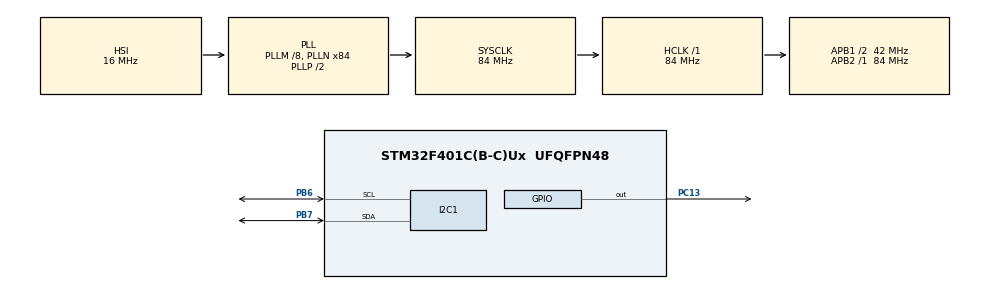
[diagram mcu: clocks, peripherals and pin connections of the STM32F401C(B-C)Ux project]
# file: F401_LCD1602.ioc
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Mcu.Family=STM32F4
Mcu.Name=STM32F401C(B-C)Ux
Mcu.Package=UFQFPN48
NVIC.PriorityGroup=NVIC_PRIORITYGROUP_4
PB6.Mode=I2C
PB6.Signal=I2C1_SCL
PB7.Mode=I2C
PB7.Signal=I2C1_SDA
PC13-ANTI_TAMP.Signal=GPIO_Output
PH0\ -\ OSC_IN.Mode=HSE-External-Oscillator
PH0\ -\ OSC_IN.Signal=RCC_OSC_IN
PH1\ -\ OSC_OUT.Mode=HSE-External-Oscillator
PH1\ -\ OSC_OUT.Signal=RCC_OSC_OUT
ProjectManager.HeapSize=0x200
ProjectManager.StackSize=0x400
ProjectManager.TargetToolchain=STM32CubeIDE
RCC.48MHZClocksFreq_Value=42000000
RCC.AHBFreq_Value=84000000
RCC.APB1CLKDivider=RCC_HCLK_DIV2
RCC.APB1Freq_Value=42000000
RCC.APB1TimFreq_Value=84000000
RCC.APB2Freq_Value=84000000
RCC.APB2TimFreq_Value=84000000
RCC.CortexFreq_Value=84000000
RCC.HCLKFreq_Value=84000000
RCC.HSE_VALUE=25000000
RCC.HSI_VALUE=16000000
RCC.LSE_VALUE=32768
RCC.PLLM=8
RCC.PLLN=84
RCC.SYSCLKFreq_VALUE=84000000
RCC.SYSCLKSource=RCC_SYSCLKSOURCE_PLLCLK
RCC.VCOOutputFreq_Value=168000000
board=custom

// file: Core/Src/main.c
/* USER CODE BEGIN Header */
/**
  ******************************************************************************
  * @file           : main.c
  * @brief          : Main program body
  ******************************************************************************
  * @attention
  *
  * <h2><center>&copy; Copyright (c) 2023 STMicroelectronics.
  * All rights reserved.</center></h2>
  *
  * This software component is licensed by ST under BSD 3-Clause license,
  * the "License"; You may not use this file except in compliance with the
  * License. You may obtain a copy of the License at:
  *                        opensource.org/licenses/BSD-3-Clause
  *
  ******************************************************************************
  */
/* USER CODE END Header */
#include "main.h"
#include "i2c.h"
#include "gpio.h"

/* USER CODE BEGIN Includes */
#include "LCD1602.h"
/* USER CODE END Includes */

/* USER CODE BEGIN PTD */
#define LCD_GREEN_ADDRESS (0x27 << 1)
#define LCD_BLUE_ADDRESS (0x26 << 1)
/* USER CODE END PTD */

void SystemClock_Config(void);

int main(void)
{

  /* MCU Configuration--------------------------------------------------------*/

  /* Reset of all peripherals, Initializes the Flash interface and the Systick. */
  HAL_Init();

  /* Configure the system clock */
  SystemClock_Config();

  /* Initialize all configured peripherals */
  MX_GPIO_Init();
  MX_I2C1_Init();
  /* USER CODE BEGIN 2 */
  LCD_Init(&hi2c1, LCD_GREEN_ADDRESS);
  LCD_Init(&hi2c1, LCD_BLUE_ADDRESS);
  HAL_Delay(1000);
  /* USER CODE END 2 */

  /* Infinite loop */
  while (1)
  {

    /* USER CODE BEGIN 3 */

	  LCD_SendStringToLine(&hi2c1, LCD_BLUE_ADDRESS, "HELLO", LCD_LINE_ONE);
	  HAL_GPIO_TogglePin(GPIOC, GPIO_PIN_13);
	  HAL_Delay(500);

	  LCD_SendStringToLine(&hi2c1, LCD_GREEN_ADDRESS, "WORLD", LCD_LINE_ONE);
	  HAL_GPIO_TogglePin(GPIOC, GPIO_PIN_13);
	  HAL_Delay(500);

	  LCD_Clear(&hi2c1, LCD_BLUE_ADDRESS);
	  HAL_Delay(500);
	  LCD_Clear(&hi2c1, LCD_GREEN_ADDRESS);
	  HAL_Delay(500);
  }
  /* USER CODE END 3 */
}

void SystemClock_Config(void)
{
  RCC_OscInitTypeDef RCC_OscInitStruct = {0};
  RCC_ClkInitTypeDef RCC_ClkInitStruct = {0};

  /** Configure the main internal regulator output voltage
  */
  __HAL_RCC_PWR_CLK_ENABLE();
  __HAL_PWR_VOLTAGESCALING_CONFIG(PWR_REGULATOR_VOLTAGE_SCALE2);
  /** Initializes the RCC Oscillators according to the specified parameters
  * in the RCC_OscInitTypeDef structure.
  */
  RCC_OscInitStruct.OscillatorType = RCC_OSCILLATORTYPE_HSI;
  RCC_OscInitStruct.HSIState = RCC_HSI_ON;
  RCC_OscInitStruct.HSICalibrationValue = RCC_HSICALIBRATION_DEFAULT;
  RCC_OscInitStruct.PLL.PLLState = RCC_PLL_ON;
  RCC_OscInitStruct.PLL.PLLSource = RCC_PLLSOURCE_HSI;
  RCC_OscInitStruct.PLL.PLLM = 8;
  RCC_OscInitStruct.PLL.PLLN = 84;
  RCC_OscInitStruct.PLL.PLLP = RCC_PLLP_DIV2;
  RCC_OscInitStruct.PLL.PLLQ = 4;
  if (HAL_RCC_OscConfig(&RCC_OscInitStruct) != HAL_OK)
  {
    Error_Handler();
  }
  /** Initializes the CPU, AHB and APB buses clocks
  */
  RCC_ClkInitStruct.ClockType = RCC_CLOCKTYPE_HCLK|RCC_CLOCKTYPE_SYSCLK
                              |RCC_CLOCKTYPE_PCLK1|RCC_CLOCKTYPE_PCLK2;
  RCC_ClkInitStruct.SYSCLKSource = RCC_SYSCLKSOURCE_PLLCLK;
  RCC_ClkInitStruct.AHBCLKDivider = RCC_SYSCLK_DIV1;
  RCC_ClkInitStruct.APB1CLKDivider = RCC_HCLK_DIV2;
  RCC_ClkInitStruct.APB2CLKDivider = RCC_HCLK_DIV1;

  if (HAL_RCC_ClockConfig(&RCC_ClkInitStruct, FLASH_LATENCY_2) != HAL_OK)
  {
    Error_Handler();
  }
}

void Error_Handler(void)
{
  __disable_irq();
  while (1)
  {
  }
}

/************************ (C) COPYRIGHT STMicroelectronics *****END OF FILE****/
